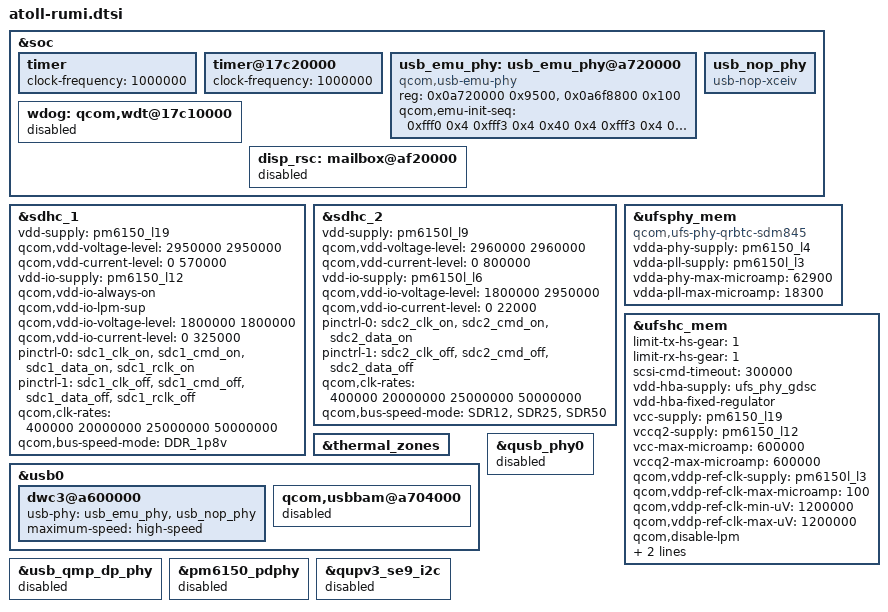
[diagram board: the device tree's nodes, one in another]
/* Copyright (c) 2019, The Linux Foundation. All rights reserved.
 *
 * This program is free software; you can redistribute it and/or modify
 * it under the terms of the GNU General Public License version 2 and
 * only version 2 as published by the Free Software Foundation.
 *
 * This program is distributed in the hope that it will be useful,
 * but WITHOUT ANY WARRANTY; without even the implied warranty of
 * MERCHANTABILITY or FITNESS FOR A PARTICULAR PURPOSE.  See the
 * GNU General Public License for more details.
 */

&soc {

	timer {
		clock-frequency = <1000000>;
	};

	timer@17c20000 {
		clock-frequency = <1000000>;
	};

	usb_emu_phy: usb_emu_phy@a720000 {
		compatible = "qcom,usb-emu-phy";
		reg = <0x0a720000 0x9500>,
			<0x0a6f8800 0x100>;
		reg-names = "base", "qcratch_base";

		qcom,emu-init-seq = <0xfff0 0x4
					0xfff3 0x4
					0x40 0x4
					0xfff3 0x4
					0xfff0 0x4
					0x100000 0x20
					0x0 0x20
					0x1a0 0x20
					0x100000 0x3c
					0x0 0x3c
					0x10060 0x3c
					0x0 0x4>;
	};

	usb_nop_phy: usb_nop_phy {
		compatible = "usb-nop-xceiv";
	};

	wdog: qcom,wdt@17c10000{
		status = "disabled";
	};

	disp_rsc: mailbox@af20000 {
		status = "disabled";
	};
};

&sdhc_1 {
	vdd-supply = <&pm6150_l19>;
	qcom,vdd-voltage-level = <2950000 2950000>;
	qcom,vdd-current-level = <0 570000>;

	vdd-io-supply = <&pm6150_l12>;
	qcom,vdd-io-always-on;
	qcom,vdd-io-lpm-sup;
	qcom,vdd-io-voltage-level = <1800000 1800000>;
	qcom,vdd-io-current-level = <0 325000>;

	pinctrl-names = "active", "sleep";
	pinctrl-0 = <&sdc1_clk_on &sdc1_cmd_on &sdc1_data_on
					&sdc1_rclk_on>;
	pinctrl-1 = <&sdc1_clk_off &sdc1_cmd_off &sdc1_data_off
					&sdc1_rclk_off>;

	qcom,clk-rates = <400000 20000000 25000000 50000000>;
	qcom,bus-speed-mode = "DDR_1p8v";

	/delete-property/qcom,devfreq,freq-table;

	status = "ok";
};

&sdhc_2 {
	vdd-supply = <&pm6150l_l9>;
	qcom,vdd-voltage-level = <2960000 2960000>;
	qcom,vdd-current-level = <0 800000>;

	vdd-io-supply = <&pm6150l_l6>;
	qcom,vdd-io-voltage-level = <1800000 2950000>;
	qcom,vdd-io-current-level = <0 22000>;

	pinctrl-names = "active", "sleep";
	pinctrl-0 = <&sdc2_clk_on  &sdc2_cmd_on &sdc2_data_on>;
	pinctrl-1 = <&sdc2_clk_off &sdc2_cmd_off &sdc2_data_off>;

	qcom,clk-rates = <400000 20000000 25000000 50000000>;
	qcom,bus-speed-mode = "SDR12", "SDR25", "SDR50";

	/delete-property/qcom,devfreq,freq-table;

	status = "ok";
};

&ufsphy_mem {
	compatible = "qcom,ufs-phy-qrbtc-sdm845";

	vdda-phy-supply = <&pm6150_l4>; /* 0.88v */
	vdda-pll-supply = <&pm6150l_l3>; /* 1.2v */
	vdda-phy-max-microamp = <62900>;
	vdda-pll-max-microamp = <18300>;

	status = "ok";
};

&ufshc_mem {
	limit-tx-hs-gear = <1>;
	limit-rx-hs-gear = <1>;
	scsi-cmd-timeout = <300000>;

	vdd-hba-supply = <&ufs_phy_gdsc>;
	vdd-hba-fixed-regulator;
	vcc-supply = <&pm6150_l19>;
	vccq2-supply = <&pm6150_l12>;
	vcc-max-microamp = <600000>;
	vccq2-max-microamp = <600000>;

	qcom,vddp-ref-clk-supply = <&pm6150l_l3>;
	qcom,vddp-ref-clk-max-microamp = <100>;
	qcom,vddp-ref-clk-min-uV = <1200000>;
	qcom,vddp-ref-clk-max-uV = <1200000>;


	qcom,disable-lpm;
	rpm-level = <0>;
	spm-level = <0>;
	status = "ok";
};

&thermal_zones {
	/delete-node/ aoss-0-lowf;
};

&usb0 {
	dwc3@a600000 {
		usb-phy = <&usb_emu_phy>, <&usb_nop_phy>;
		maximum-speed = "high-speed";
	};
	qcom,usbbam@a704000 {
		status = "disabled";
	};
};

&qusb_phy0 {
	status = "disabled";
};

&usb_qmp_dp_phy {
	status = "disabled";
};

&pm6150_pdphy {
	status = "disabled";
};

&qupv3_se9_i2c {
	status = "disabled";
};
